# cslr_mdio register map
Vendor: Texas Instruments
Peripheral module from a debugger description file (folder TCI6484_C6457).
Registers are 32-bit, access not given, reset 0x0 unless marked. A register's access mark holds for its fields unless they carry their own. Offsets are as the file gives them; lines under a group give offsets from that group; [hi:lo] are bit positions; {n}, {i} and the like mark numbered series; 'fields as' and 'values as' point back to an identical list; <NAME> marks a mode.

## MDIO — Management Data Input/Output
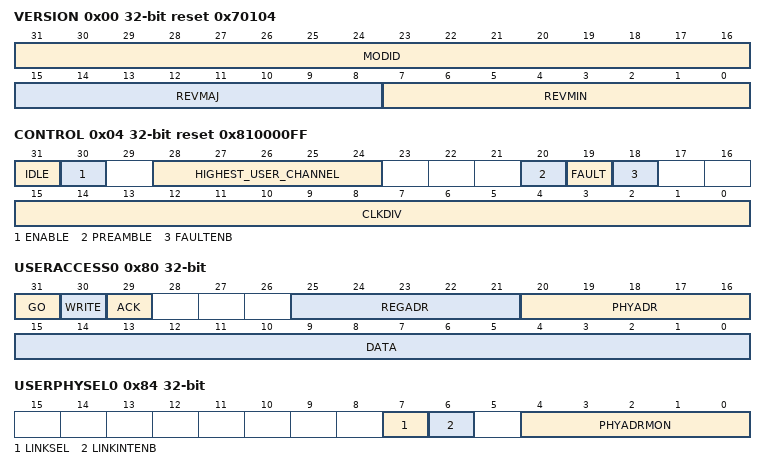
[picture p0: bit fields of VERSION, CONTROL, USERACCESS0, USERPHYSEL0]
0x00 VERSION ro reset 0x70104 — MDIO Version Register
  [31:16] MODID — Identifies the type of peripheral
  [15:8] REVMAJ — Management Interface Module major revision value
  [7:0] REVMIN — Management Interface Module minor revision value
0x04 CONTROL reset 0x810000FF — MDIO Control Register
  [31] IDLE ro — State machine IDLE status bit
    0=NO (State machine is not in idle state); 1=YES (State machine is in idle state)
  [30] ENABLE rw — State machine enable control bit. . If the MDIO state machine is active at the time it is disabled, it will complete the current operation before halting and setting the idle bit.
    0=NO (Disables the MDIO state machine); 1=YES (Enable the MDIO state machine)
  [28:24] HIGHEST_USER_CHANNEL ro — Highest user channel that is available in the module. It is currently set to 1. This implies that MDIOUserAccess1 is the highest available user access channel.
  [20] PREAMBLE rw — Preamble disable
    0=ENABLED (Standard MDIO preamble is used); 1=DISABLED (Disables this device from sending MDIO frame preambles)
  [19] FAULT — Fault indicator. This bit is set to 1 if the MDIO pins fail to read back what the device is driving onto them. This indicates a physical layer fault and the module state machine is reset. Writing a 1 to it clears this bit. (access RWC)
    0=NO (No failure); 1=YES (Physical layer fault; the MDIO state machine is reset)
  [18] FAULTENB rw — Fault detect enable. This bit has to be set to 1 to enable the physical layer fault detection.
    0=NO (Disables the physical layer fault detection); 1=YES (Enables the physical layer fault detection)
  [15:0] CLKDIV rw — Clock Divider bits. This field specifies the division ratio between VBUS peripheral clock and the frequency of MDCLK. MDCLK is disabled when CLKDIV is set to 0. MDCLK frequency = peripheral clock frequency/(CLKDIV + 1).
0x08 ALIVE — PHY alive status register
  [31:0] ALIVE — MDIO Alive bits. Each of the 32 bits of this register is set if the most recent access to the PHY with address corresponding to the register bit number was acknowledged by the PHY, the bit is reset if the PHY fails to acknowledge the access. Both the user and polling accesses to a PHY will cause the corresponding alive bit to be updated. The alive bits are only meant to be used to give an indication of the presence or not of a PHY with the corresponding address. Writing a 1 to any bit will clear it, writing a 0 has no effect. (access RWC)
    0=DEAD (The PHY fails to acknowledge the access); 1=ALIVE (The most recent access to the PHY with an address corresponding to the register bit number was acknowledged by the PHY.)
0x0C LINK ro — PHY Link Status Register
  [31:0] LINK — MDIO Link state bits. This register is updated after a read of the Generic Status Register of a PHY. The bit is set if the PHY with the corresponding address has link and the PHY acknowledges the read transaction. The bit is reset if the PHY indicates it does not have link or fails to acknowledge the read transaction. Writes to the register have no effect.
    0=NOLINK (The PHY indicates it does not have a link or fails to acknowledge the read transaction); 1=LINK (The PHY with the corresponding address has a link and the PHY acknowledges the read transaction)
0x10 LINKINTRAW — MDIO Link Status Change Interrupt (Unmasked) Register
  [1:0] LINKINTRAW — MDIO Link change event, raw value. When asserted, a bit indicates that there was an MDIO link change event (i.e. change in the LINK register) corresponding to the PHY address in the USERPHYSEL register. LINKINTRAW[0] and LINKINTRAW[1] correspond to USERPHYSEL0 and USERPHYSEL1, respectively. Writing a 1 will clear the event and writing 0 has no effect. (access RWC)
0x14 LINKINTMASKED — MDIO Link Status Change Interrupt (Masked) Register
  [1:0] LINKINTMASKED — MDIO Link change interrupt, masked value. . When asserted, a bit indicates that there was an MDIO link change event (i.e. change in the LINK register) corresponding to the PHY address in the USERPHYSEL register and the corresponding LINKINTENB bit was set. LINKINTRAW[0] and LINKINTRAW[1] correspond to USERPHYSEL0 and USERPHYSEL1, respectively. Writing a 1 will clear the event and writing 0 has no effect. (access RWC)
    1=CLEAR_EVENT
0x20 USERINTRAW — MDIO User Command Complete Interrupt (Unmasked) Register
  [1:0] USERINTRAW — MDIO User command complete event bits. When asserted, a bit indicates that the previously scheduled PHY read or write command using that particular USERACCESS register has completed. Writing a 1 will clear the event and writing 0 has no effect. (access RWC)
0x24 USERINTMASKED — MDIO User Command Complete Interrupt (Masked) Register
  [1:0] USERINTMASKED — Masked value of MDIO User command complete interrupt. When asserted, a bit indicates that the previously scheduled PHY read or write command using that particular USERACCESS register has completed and the corresponding USERINTMASKSET bit is set to 1. Writing a 1 will clear the interrupt and writing 0 has no effect. (access RWC)
    1=CLEAR_EVENT
0x28 USERINTMASKSET — MDIO User Command Complete Interrupt Mask Set Register
  [1:0] USERINTMASKSET — MDIO user interrupt mask set for USERINTMASKED[1:0] respectively. Setting a bit to 1 will enable MDIO user command complete interrupts for that particular USERACCESS register. MDIO user interrupt for a particular USERACCESS register is disabled if the corresponding bit is 0. Writing a 0 to this register has no effect. (access RWC)
0x2C USERINTMASKCLEAR — MDIO User Command Complete Interrupt Mask Clear Register
  [1:0] USERINTMASKCLEAR — MDIO user command complete interrupt mask clear for USERINTMASKED[1:0] respectively. Setting a bit to 1 will disable further user command complete interrupts for that particular USERACCESS register. Writing a 0 to this register has no effect. (access RWC)
0x80 USERACCESS0 — MDIO User Access Register 0
  [31] GO — Go bit. Writing a 1 to this bit causes the MDIO state machine to perform an MDIO access when it is convenient for it to do so, this is not an instantaneous process. Writing a 0 to this bit has no effect. This bit is write able only if the MDIO state machine is enabled. This bit will self clear when the requested access has been completed. Any writes to the USERACCESS0 register are blocked when the go bit is 1. (access RWS)
  [30] WRITE rw — Write enable bit. Setting this bit to a 1 causes the MDIO transaction to be a register write, otherwise it is a register read.
    0=READ (The user command is a read operation); 1=WRITE (The user command is a write operation)
  [29] ACK rw — Acknowledge bit. This bit is set if the PHY acknowledged the read transaction.
  [25:21] REGADR rw — Register address bits. This field specifies the PHY register to be accessed for this transaction
  [20:16] PHYADR rw — PHY address bits. This field specifies the PHY to be accesses for this transaction
  [15:0] DATA rw — User data bits. These bits specify the data value read from or to be written to the specified PHY register.
0x84 USERPHYSEL0 — MDIO User PHY Select Register 0
  [7] LINKSEL rw — Link status determination select bit. Default value is 0 which implies that the link status is determined by the MDIO state machine. This is the only option supported on this device.
    0=MDIO
  [6] LINKINTENB rw — Link change interrupt enable. Set to 1 to enable link change status interrupts for PHY address specified in PHYADRMON. Link change interrupts are disabled if this bit is set to 0.
    0=DISABLE (Link change interrupts are disabled); 1=ENABLE (Link change status interrupts for PHY address specified in PHYADDRMON bits are enabled)
  [4:0] PHYADRMON rw — PHY address whose link status is to be monitored
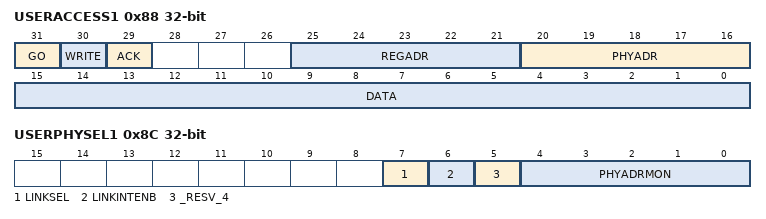
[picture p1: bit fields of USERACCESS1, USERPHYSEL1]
0x88 USERACCESS1 — MDIO User Access Register 1
  fields as USERACCESS0
0x8C USERPHYSEL1 — MDIO User PHY Select Register 1
  [7] LINKSEL rw — Link status determination select bit. Default value is 0 which implies that the link status is determined by the MDIO state machine. This is the only option supported on this device.
    0=MDIO
  [6] LINKINTENB rw
    values as USERPHYSEL0.LINKINTENB
  [5] _RESV_4 — PHY address whose link status is to be monitored (access N)
  [4:0] PHYADRMON rw — PHY address whose link status is to be monitored
